# RA6M2 register map
Vendor: Renesas Electronics Corporation; Series: RA6; File version: 1.1
CPU: CM4 r0p1, little endian, MPU, FPU, VTOR, 4 interrupt priority bits
Registers are 8-bit, read-write, reset 0x0 unless marked. A register's access mark holds for its fields unless they carry their own. Offsets are from the block's base; [hi:lo] are bit positions; {n}, {i} and the like mark numbered series; 'fields as' and 'values as' point back to an identical list.

## TSN — Temperature Sensor
Base 0x4005D000
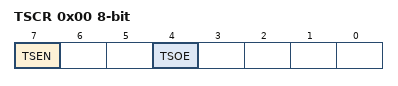
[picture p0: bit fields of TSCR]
0x00 TSCR — Temperature Sensor Control Register
  [7] TSEN — Temperature Sensor Output Enable
    0=Stops the temperature sensor; 1=Starts the temperature sensor
  [4] TSOE — Temperature Sensor Enable
    0=Disables output from the temperature sensor to the 12-bit A/D converter; 1=Enables output from the temperature sensor to the 12-bit A/D converter

## CRC — CRC Calculator
Base 0x40074000
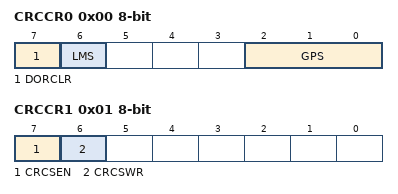
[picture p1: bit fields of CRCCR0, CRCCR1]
0x00 CRCCR0 — CRC Control Register0
  [7] DORCLR wo — CRCDOR Register Clear
    0=No effect; 1=Clears the CRCDOR register
  [6] LMS — CRC Calculation Switching
    0=Generates CRC for LSB first communication; 1=Generates CRC for MSB first communication
  [2:0] GPS — CRC Generating Polynomial Switching
    0=No calculation is executed; 1=8-bit CRC-8 (X8 + X2 + X + 1); 2=16-bit CRC-16 (X16 + X15 + X2 + 1); 3=16-bit CRC-CCITT (X16 + X12 + X5 + 1); 4=32-bit CRC-32 (X32+X26+X23+X22+X16+X12+X11+X10+X8+X7+X5+X4+X2+X+1); 5=32-bit CRC-32C (X32+X28+X27+X26+ X25+X23+X22+X20+X19+X18+X14+X13+X11+X10+X9+X8+X6+1); other=others (No calculation is executed.)
0x01 CRCCR1 — CRC Control Register1
  [7] CRCSEN — Snoop enable bit
    0=Disabled; 1=Enabled
  [6] CRCSWR — Snoop-on-write/read switch bit
    0=Snoop-on-read; 1=Snoop-on-write
0x04 CRCDIR 32-bit — CRC Data Input Register
  [31:0] CRCDIR — Calculation input Data (Case of CRC-32, CRC-32C )
0x04 CRCDIR_BY (alternate view of CRCDIR) — CRC Data Input Register (byte access)
  [7:0] CRCDIR_BY — Calculation input Data ( Case of CRC-8, CRC-16 or CRC-CCITT )
0x08 CRCDOR 32-bit — CRC Data Output Register
  [31:0] CRCDOR — Calculation output Data (Case of CRC-32, CRC-32C )
0x08 CRCDOR_HA 16-bit (alternate view of CRCDOR) — CRC Data Output Register (halfword access)
  [15:0] CRCDOR_HA — Calculation output Data (Case of CRC-16 or CRC-CCITT )
0x08 CRCDOR_BY (alternate view of CRCDOR) — CRC Data Output Register(byte access)
  [7:0] CRCDOR_BY — Calculation output Data (Case of CRC-8 )
0x0C CRCSAR 16-bit — Snoop Address Register
  [13:0] CRCSA — snoop address bitSet the I/O register address to snoop
    3=SCI0.TDR; 5=SCI0.RDR; 35=SCI1.TDR; 37=SCI1.RDR; 67=SCI2.TDR; 69=SCI2.RDR; 99=SCI3.TDR; 101=SCI3.RDR; 131=SCI4.TDR; 133=SCI4.RDR; 163=SCI5.TDR; 165=SCI5.RDR; 195=SCI6.TDR; 197=SCI6.RDR; 227=SCI7.TDR; 229=SCI7.RDR; 0x103=SCI8.TDR; 0x105=SCI8.RDR; 0x123=SCI9.TDR; 0x125=SCI9.RDR; other=others (Settings other than above are prohibited.)

## ELC — Event Link Controller
Base 0x40041000
0x00 ELCR — Event Link Controller Register
  [7] ELCON — All Event Link Enable
    0=Disable ELC function; 1=Enable ELC function
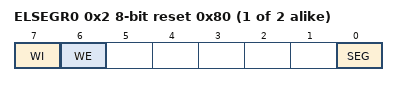
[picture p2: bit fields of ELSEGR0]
{0x2+2i} ELSEGR{i} (i=0..1) reset 0x80 — Event Link Software Event Generation Register {i}
  [7] WI wo — ELSEGR Register Write Disable
    0=Enable writes to ELSEGR register; 1=Disable writes to ELSEGR register
  [6] WE — SEG Bit Write Enable
    0=Disable writes to SEG bit; 1=Enable writes to SEG bit
  [0] SEG wo — Software Event Generation
    0=Normal operation; 1=Generate a software event
{0x10+4i} ELSR{i} (i=0..18) 16-bit — Event Link Setting Register {i}
  [8:0] ELS — Event Link Select
    0=Event output to the corresponding peripheral module is disabled; other=others (Set the number for the event signal to be linked.)

## PORT0 — Port 0 Control Registers
Base 0x40040000
Same registers: PORT5 0x400400A0, PORT6 0x400400C0, PORT7 0x400400E0, PORT8 0x40040100
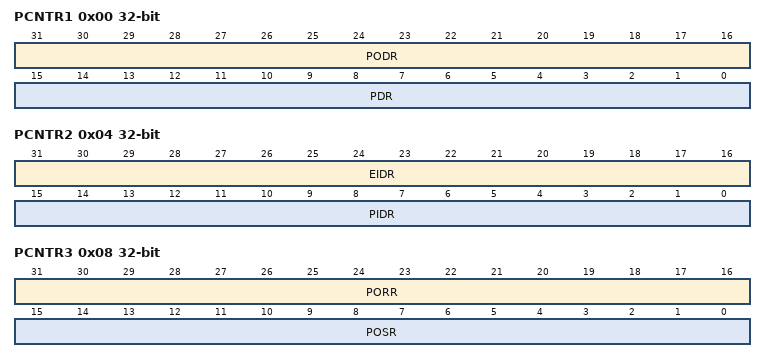
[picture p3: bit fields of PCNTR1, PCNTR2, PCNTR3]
0x00 PCNTR1 32-bit — Port Control Register 1
  [31:16] PODR — Pmn Output Data
    0=Low output; 1=High output
  [15:0] PDR — Pmn Direction
    0=Input (functions as an input pin); 1=Output (functions as an output pin)
0x00 PODR 16-bit (alternate view of PCNTR1) — Output data register
  [15:0] PODR — Pmn Output Data
    0=Low output; 1=High output
0x02 PDR 16-bit (alternate view of PCNTR1) — Data direction register
  [15:0] PDR — Pmn Direction
    values as PCNTR1.PDR
0x04 PCNTR2 32-bit ro (reset mask 0xFFFF0000) — Port Control Register 2
  [31:16] EIDR — Pmn Event Input Data
    0=Low input; 1=High input
  [15:0] PIDR — Pmn Input Data
    0=Low input; 1=High input
0x06 PIDR 16-bit ro reset not defined (alternate view of PCNTR2) — Input data register
  [15:0] PIDR — Pmn Input Data
    0=Low input; 1=High input
0x08 PCNTR3 32-bit wo — Port Control Register 3
  [31:16] PORR — Pmn Output Reset
    0=No affect to output; 1=Low output
  [15:0] POSR — Pmn Output Set
    0=No affect to output; 1=High output
0x08 PORR 16-bit wo (alternate view of PCNTR3) — Output reset register
  [15:0] PORR — Pmn Output Reset
    0=No affect to output; 1=Low output
0x0A POSR 16-bit wo (alternate view of PCNTR3) — Output set register
  [15:0] POSR — Pmn Output Set
    0=No affect to output; 1=High output

## PORT1 — Port 1 Control Registers
Base 0x40040020
Same registers: PORT2 0x40040040, PORT3 0x40040060, PORT4 0x40040080
Registers as PORT0; these are added or differ:
0x04 EIDR 16-bit ro reset not defined (alternate view of PCNTR2) — Event input data register
  [15:0] EIDR — Pmn Event Input Data
    0=Low input; 1=High input
0x08 PORR 16-bit wo (alternate view of PCNTR3) — Output set register
  [15:0] PORR — Pmn Output Reset
    0=No affect to output; 1=Low output
0x0A POSR 16-bit wo (alternate view of PCNTR3) — Output reset register
  [15:0] POSR — Pmn Output Set
    0=No affect to output; 1=High output
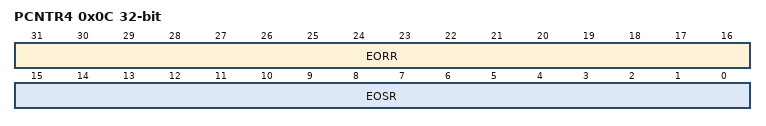
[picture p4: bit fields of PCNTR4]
0x0C PCNTR4 32-bit — Port Control Register 4
  [31:16] EORR — Pmn Event Output Reset
    0=No affect to output; 1=Low output
  [15:0] EOSR — Pmn Event Output Set
    0=No affect to output; 1=High output
0x0C EORR 16-bit (alternate view of PCNTR4) — Event output set register
  [15:0] EORR — Pmn Event Output Reset
    0=No affect to output; 1=Low output
0x0E EOSR 16-bit (alternate view of PCNTR4) — Event output reset register
  [15:0] EOSR — Pmn Event Output Set
    0=No affect to output; 1=High output
